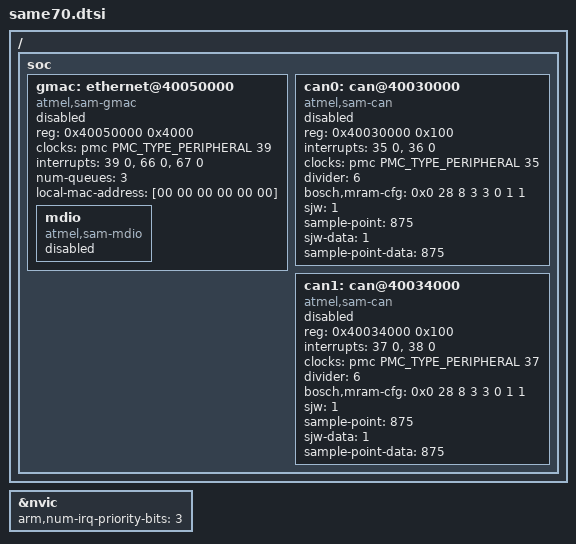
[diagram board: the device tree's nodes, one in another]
/*
 * Copyright (c) 2017 Piotr Mienkowski
 * Copyright (c) 2017 Justin Watson
 *
 * SPDX-License-Identifier: Apache-2.0
 */

 #include <atmel/sams70.dtsi>

/ {
	soc {
		gmac: ethernet@40050000 {
			compatible = "atmel,sam-gmac";
			reg = <0x40050000 0x4000>;
			clocks = <&pmc PMC_TYPE_PERIPHERAL 39>;
			interrupts = <39 0>, <66 0>, <67 0>;
			interrupt-names = "gmac", "q1", "q2";
			num-queues = <3>;
			local-mac-address = [00 00 00 00 00 00];
			status = "disabled";

			mdio: mdio {
				compatible = "atmel,sam-mdio";
				status = "disabled";
			};
		};

		can0: can@40030000 {
			compatible = "atmel,sam-can";
			reg = <0x40030000 0x100>;
			interrupts = <35 0>, <36 0>;
			interrupt-names = "LINE_0", "LINE_1";
			clocks = <&pmc PMC_TYPE_PERIPHERAL 35>;
			divider = <6>;
			bosch,mram-cfg = <0x0 28 8 3 3 0 1 1>;
			sjw = <1>;
			sample-point = <875>;
			sjw-data = <1>;
			sample-point-data = <875>;
			status = "disabled";
		};

		can1: can@40034000 {
			compatible = "atmel,sam-can";
			reg = <0x40034000 0x100>;
			interrupts = <37 0>, <38 0>;
			interrupt-names = "LINE_0", "LINE_1";
			clocks = <&pmc PMC_TYPE_PERIPHERAL 37>;
			divider = <6>;
			bosch,mram-cfg = <0x0 28 8 3 3 0 1 1>;
			sjw = <1>;
			sample-point = <875>;
			sjw-data = <1>;
			sample-point-data = <875>;
			status = "disabled";
		};
	};
};

&nvic {
	arm,num-irq-priority-bits = <3>;
};
